AUTOSAR XML (schema 00054)
standard types defined: sint16
package /AUTOSAR_AISpecification/ApplicationDataTypes
  app type AgSpd2: category=VALUE, sw-calibration-access=READ-ONLY, compu-method=AgSpd2, range phys -5..5 rad/s, sw-intended-resolution=0.0009765625, unit=rad/s  # Angle Speed 2 | Generic data type for angle speed
package /AUTOSAR_AISpecification/CompuMethods
  compu method AgSpd2: raw=phys*1024 for phys -5..5; unit rad/s  # Angle Speed 2 | Generic data type for angle speed
package /AUTOSAR_AISpecification/PhysicalDimensions
  physical dimension TiNeg1_2: time-exp=-1  # Angular Speed
package /AUTOSAR_AISpecification/PortInterfaces
  sender receiver interface RoadWhlAgSpd1  # Road Wheel Angle Speed 1 | Generic interface for road wheel angle speed
    data RoadWhlAgSpd: type=AgSpd2
package /AUTOSAR_AISpecification/Units
  unit RadPerSec: display-name=rad/s, factor-si-to-unit=1.0, physical-dimension=TiNeg1_2  # Radian per Second | SI derived unit of angular velocity
package /CommunicationClusters
  can cluster CanCluster: baudrate=500000, protocol-name=CAN
    can physical channel CanPhysicalChannel: comm-connectors=WhlSpd_CanConnector
      frame CanFrame_EcuWhlSpd_RoadWhlAgSpd_Tx: id 0x100, from WheelSpeed, frame-length=8, can-addressing-mode=STANDARD, can-frame-tx-behavior=CAN-20
        carries pdu ISIPdu_EcuWhlSpd_RoadWhlAgSpd_Tx: packing-byte-order=little-endian, start-position=0, update-indication-bit-position=0
        pdu ISIPdu_EcuWhlSpd_RoadWhlAgSpd_Tx: length=8, unused-bit-pattern=0
          signal ISig_EcuWhlSpd_RoadWhlAgSpd_Tx: start 0, 16 bit, little-endian, system signal SysSig_EcuWhlSpd_RoadWhlAgSpd_Tx, base-type=sint16, compu-method=AgSpd2
package /EcuInstances
  ecu instance WheelSpeed
    can communication controller WhlSpd_CanController: wake-up-by-controller-supported=false, can-controller-attributes=can-controller-configuration={prop-seg=8, sync-jump-width=3, time-seg-1=7, time-seg-2=4}
    can communication connector WhlSpd_CanConnector: comm-controller=WhlSpd_CanController
    ecu partition EcuPartWhlSpd
package /EcuWheelSpeed
  hw element WheelSpeed: hw-type=EcuType, hw-category=Ecu
    hw pin group CanBus
package /HwCategorys
  hw category Ecu
  hw category SensorActuator
  hw category Analog
package /HwTypes
  hw type EcuType: hw-category=Ecu
  hw type SensorActuatorType: hw-category=SensorActuator
  hw type IoAType: hw-category=Analog
package /Pkg_ImplementationDataTypes
  impl type AgSpd2_Impl: implementation-data-type=sint16
package /Pkg_MappingSets
  data type mapping set DataTypeMappingSet_AgSpd: data-type-map{application-data-type=AgSpd2, implementation-data-type=AgSpd2_Impl}
package /SwComponentTypes
  composition sw component type WheelSpeedComposition
    provide port WhlSpdConsoldOutp: provided-interface=RoadWhlAgSpd1
    component CPT_WhlSpdVirt: type=WhlSpdVirt
    component CPT_WhlSpdSnsr: type=WhlSpdSnsr
    connect CPT_WhlSpdVirt.WhlSpdMeasdOutp -> CPT_WhlSpdSnsr.WhlSpdMeasdInp
    delegate CPT_WhlSpdSnsr.WhlSpdConsoldOutp <-> outer port WheelSpeedComposition/WhlSpdConsoldOutp
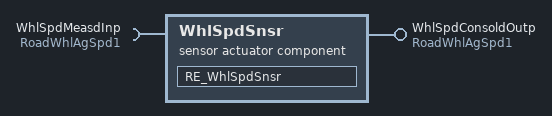
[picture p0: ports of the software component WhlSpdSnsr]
  sensor actuator sw component type WhlSpdSnsr: sensor-actuator=SensorActuatorType
    provide port WhlSpdConsoldOutp: provided-interface=RoadWhlAgSpd1
    require port WhlSpdMeasdInp: nonqueued-receiver-com-spec{data-element=RoadWhlAgSpd, init-value=Default_WhlSpdMeasdInp:0}, required-interface=RoadWhlAgSpd1
    behavior WhlSpdSnsr_IB: data-type-mapping=DataTypeMappingSet_AgSpd, supports-multiple-instantiation=true
      data received event DRE_WhlSpdMeasdInp: start-on-event=RE_WhlSpdSnsr, data=WhlSpdMeasdInp.RoadWhlAgSpd
      runnable RE_WhlSpdSnsr: minimum-start-interval=0.01
        data-read-access:
          access DRA_WhlSpdMeasdInp: accessed-variable=WhlSpdMeasdInp.RoadWhlAgSpd
        data-send-points:
          access DSP_WhlSpdConsoldOutp: accessed-variable=WhlSpdConsoldOutp.RoadWhlAgSpd
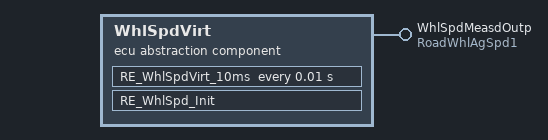
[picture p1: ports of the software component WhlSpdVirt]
  ecu abstraction sw component type WhlSpdVirt: hardware-element=IoAType
    provide port WhlSpdMeasdOutp: provided-interface=RoadWhlAgSpd1
    behavior WhlSpdVirt_IB: data-type-mapping=DataTypeMappingSet_AgSpd
      timing event TE_10ms: start-on-event=RE_WhlSpdVirt_10ms, period=0.01
      init event IE_WhlSpd_Init: start-on-event=RE_WhlSpd_Init
      runnable RE_WhlSpdVirt_10ms
        data-write-access:
          access DWA_WhlSpdMeasdOutp: accessed-variable=WhlSpdMeasdOutp.RoadWhlAgSpd
      runnable RE_WhlSpd_Init
package /System
  composition sw component type TopLevelComposition
    provide port WhlSpdConsoldOutp: provided-interface=RoadWhlAgSpd1
    component CPT_WheelSpeedComposition: type=WheelSpeedComposition
    delegate CPT_WheelSpeedComposition.WhlSpdConsoldOutp <-> outer port TopLevelComposition/WhlSpdConsoldOutp
package /Systems
  system PF_System: category=SYSTEM_EXTRACT, ecu-extract-version=1.0.0, system-version=1.0.0
    system mapping SystemMapping: sender-receiver-to-signal-mapping{data-element=RootSwCompositionPrototype.WhlSpdConsoldOutp.RoadWhlAgSpd, system-signal=SysSig_EcuWhlSpd_RoadWhlAgSpd_Tx}
      application partition to ecu partition mapping AppPartWhlSpd_EcuPartWhlSpd: application-partition=AppPartWhlSpd, ecu-partition=EcuPartWhlSpd
      sw-mappings:
        swc to ecu mapping SWcToECUMapping_WhlSpd: component=RootSwCompositionPrototype.CPT_WheelSpeedComposition, controlled-hw-element=WheelSpeed, ecu-instance=WheelSpeed, processing-unit=WheelSpeed
      swc to application partition mapping SwcToApplicationPartition_AppPartWhlSpd: application-partition=AppPartWhlSpd, sw-component-prototype=RootSwCompositionPrototype.CPT_WheelSpeedComposition
    root-software-compositions:
      root sw composition prototype RootSwCompositionPrototype: software-composition=TopLevelComposition
  application partition AppPartWhlSpd
